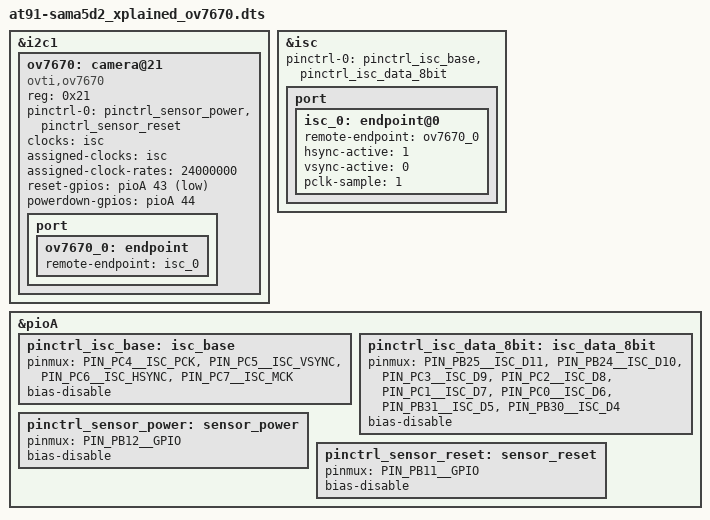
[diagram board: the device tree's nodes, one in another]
// SPDX-License-Identifier: GPL-2.0+ OR MIT
/dts-v1/;
/plugin/;

#include "sama5d2-pinfunc.h"
#include <dt-bindings/gpio/gpio.h>

&i2c1 {
	ov7670: camera@21 {
		compatible = "ovti,ov7670";
		reg = <0x21>;
		pinctrl-names = "default";
		pinctrl-0 = <&pinctrl_sensor_power &pinctrl_sensor_reset>;
		clocks = <&isc>;
		clock-names = "xclk";
		assigned-clocks = <&isc>;
		assigned-clock-rates = <24000000>;
		reset-gpios = <&pioA 43 GPIO_ACTIVE_LOW>;
		powerdown-gpios = <&pioA 44 GPIO_ACTIVE_HIGH>;

		port {
			ov7670_0: endpoint {
				remote-endpoint = <&isc_0>;
			};
		};
	};
};

&isc {
	pinctrl-names = "default";
	pinctrl-0 = <&pinctrl_isc_base &pinctrl_isc_data_8bit>;
	status = "okay";

	port {
		isc_0: endpoint@0 {
			remote-endpoint = <&ov7670_0>;
			hsync-active = <1>;
			vsync-active = <0>;
			pclk-sample = <1>;
		};
	};
};

&pioA {
	pinctrl_isc_base: isc_base {
		pinmux = <PIN_PC4__ISC_PCK>,
			 <PIN_PC5__ISC_VSYNC>,
			 <PIN_PC6__ISC_HSYNC>,
			 <PIN_PC7__ISC_MCK>;
		bias-disable;
	};

	pinctrl_isc_data_8bit: isc_data_8bit {
		pinmux = <PIN_PB25__ISC_D11>,
			 <PIN_PB24__ISC_D10>,
			 <PIN_PC3__ISC_D9>,
			 <PIN_PC2__ISC_D8>,
			 <PIN_PC1__ISC_D7>,
			 <PIN_PC0__ISC_D6>,
			 <PIN_PB31__ISC_D5>,
			 <PIN_PB30__ISC_D4>;
		bias-disable;
	};

	pinctrl_sensor_power: sensor_power {
		pinmux = <PIN_PB12__GPIO>;
		bias-disable;
	};

	pinctrl_sensor_reset: sensor_reset {
		pinmux = <PIN_PB11__GPIO>;
		bias-disable;
	};
};
